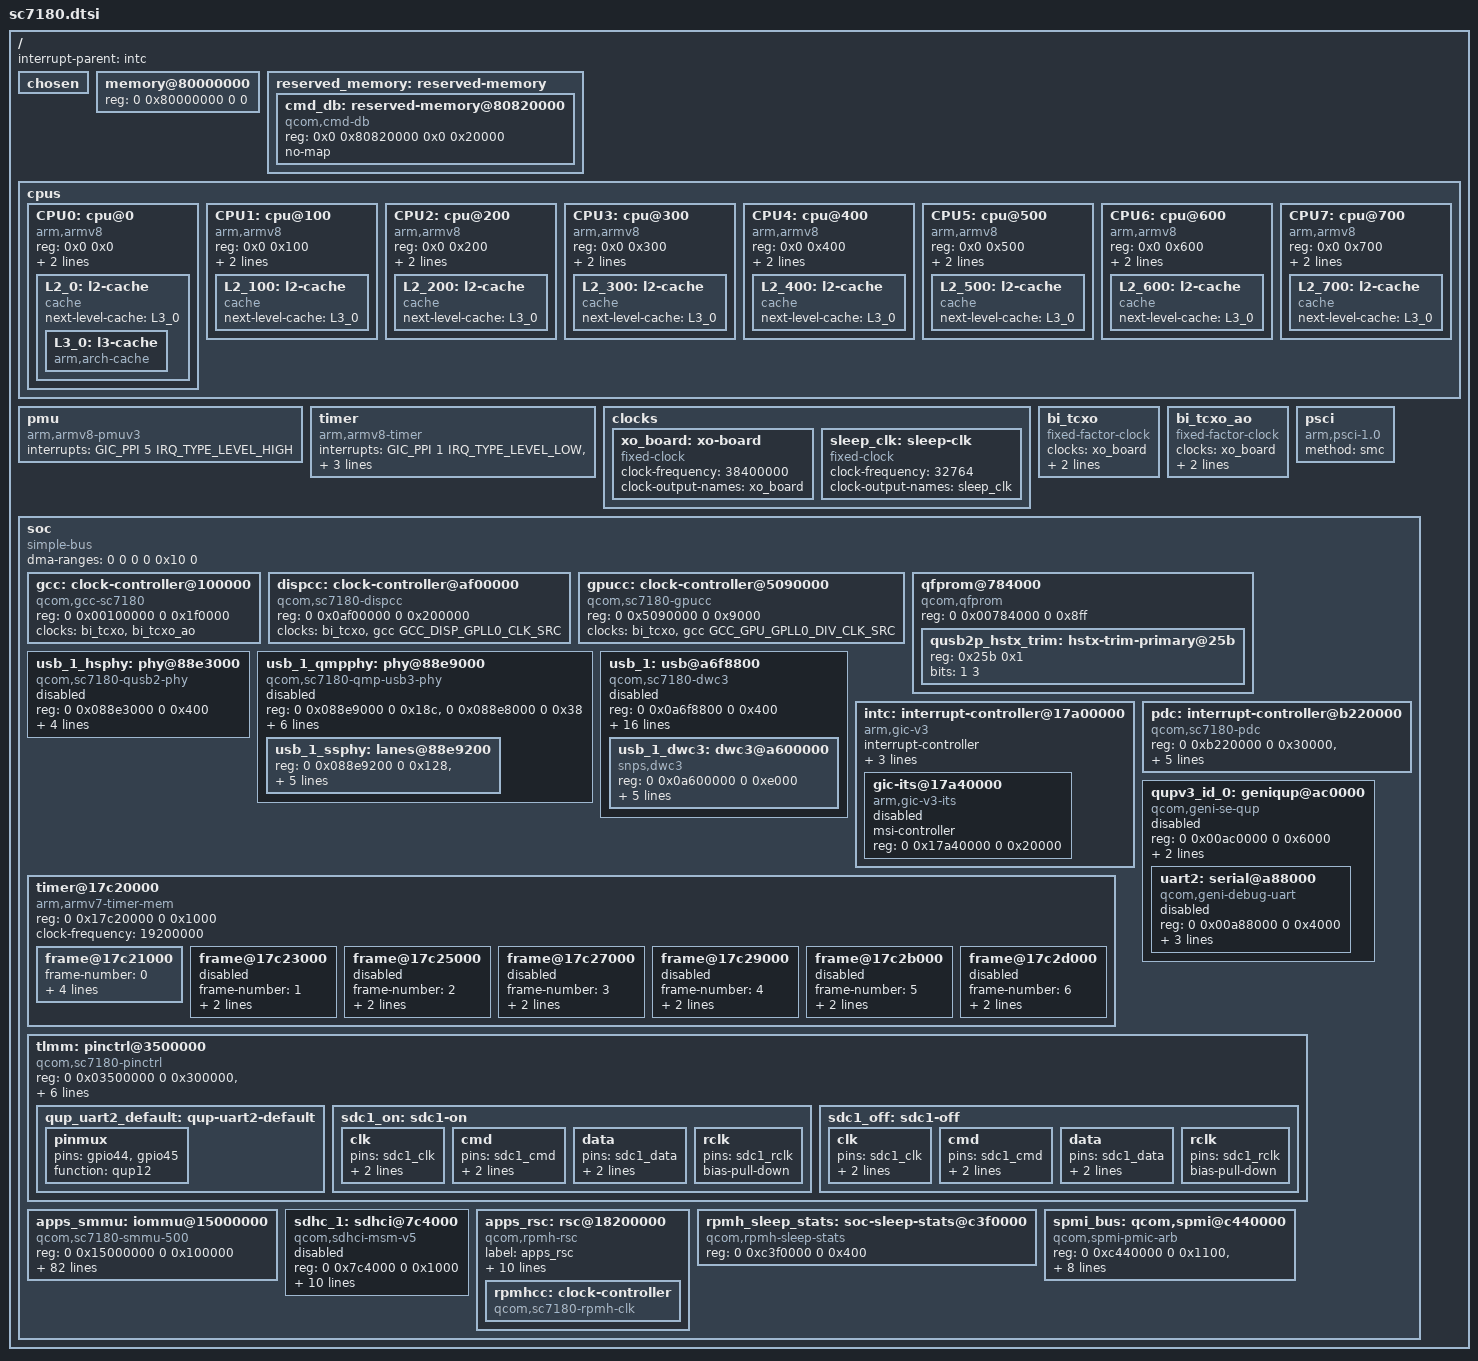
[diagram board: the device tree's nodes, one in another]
// SPDX-License-Identifier: GPL-2.0
/*
 * SC7180 SoC device tree source
 *
 * Copyright (c) 2019, The Linux Foundation. All rights reserved.
 */

#include <dt-bindings/interrupt-controller/arm-gic.h>
#include <dt-bindings/clock/qcom,dispcc-sc7180.h>
#include <dt-bindings/clock/qcom,gcc-sc7180.h>
#include <dt-bindings/clock/qcom,gpucc-sc7180.h>
#include <dt-bindings/soc/qcom,rpmh-rsc.h>
#include <dt-bindings/phy/phy-qcom-qusb2.h>

/ {
	interrupt-parent = <&intc>;

	#address-cells = <2>;
	#size-cells = <2>;

	chosen { };

	memory@80000000 {
		device_type = "memory";
		/* We expect the bootloader to fill in the size */
		reg = <0 0x80000000 0 0>;
	};

	reserved_memory: reserved-memory {
		#address-cells = <2>;
		#size-cells = <2>;
		ranges;

		cmd_db: reserved-memory@80820000 {
			reg = <0x0 0x80820000 0x0 0x20000>;
			compatible = "qcom,cmd-db";
			no-map;
		};
	};

	cpus {
		#address-cells = <2>;
		#size-cells = <0>;

		CPU0: cpu@0 {
			device_type = "cpu";
			compatible = "arm,armv8";
			reg = <0x0 0x0>;
			enable-method = "psci";
			next-level-cache = <&L2_0>;
			L2_0: l2-cache {
				compatible = "cache";
				next-level-cache = <&L3_0>;
				L3_0: l3-cache {
					compatible = "arm,arch-cache";
				};
			};
		};

		CPU1: cpu@100 {
			device_type = "cpu";
			compatible = "arm,armv8";
			reg = <0x0 0x100>;
			enable-method = "psci";
			next-level-cache = <&L2_100>;
			L2_100: l2-cache {
				compatible = "cache";
				next-level-cache = <&L3_0>;
			};
		};

		CPU2: cpu@200 {
			device_type = "cpu";
			compatible = "arm,armv8";
			reg = <0x0 0x200>;
			enable-method = "psci";
			next-level-cache = <&L2_200>;
			L2_200: l2-cache {
				compatible = "cache";
				next-level-cache = <&L3_0>;
			};
		};

		CPU3: cpu@300 {
			device_type = "cpu";
			compatible = "arm,armv8";
			reg = <0x0 0x300>;
			enable-method = "psci";
			next-level-cache = <&L2_300>;
			L2_300: l2-cache {
				compatible = "cache";
				next-level-cache = <&L3_0>;
			};
		};

		CPU4: cpu@400 {
			device_type = "cpu";
			compatible = "arm,armv8";
			reg = <0x0 0x400>;
			enable-method = "psci";
			next-level-cache = <&L2_400>;
			L2_400: l2-cache {
				compatible = "cache";
				next-level-cache = <&L3_0>;
			};
		};

		CPU5: cpu@500 {
			device_type = "cpu";
			compatible = "arm,armv8";
			reg = <0x0 0x500>;
			enable-method = "psci";
			next-level-cache = <&L2_500>;
			L2_500: l2-cache {
				compatible = "cache";
				next-level-cache = <&L3_0>;
			};
		};

		CPU6: cpu@600 {
			device_type = "cpu";
			compatible = "arm,armv8";
			reg = <0x0 0x600>;
			enable-method = "psci";
			next-level-cache = <&L2_600>;
			L2_600: l2-cache {
				compatible = "cache";
				next-level-cache = <&L3_0>;
			};
		};

		CPU7: cpu@700 {
			device_type = "cpu";
			compatible = "arm,armv8";
			reg = <0x0 0x700>;
			enable-method = "psci";
			next-level-cache = <&L2_700>;
			L2_700: l2-cache {
				compatible = "cache";
				next-level-cache = <&L3_0>;
			};
		};
	};

	pmu {
		compatible = "arm,armv8-pmuv3";
		interrupts = <GIC_PPI 5 IRQ_TYPE_LEVEL_HIGH>;
	};

	timer {
		compatible = "arm,armv8-timer";
		interrupts = <GIC_PPI 1 IRQ_TYPE_LEVEL_LOW>,
			     <GIC_PPI 2 IRQ_TYPE_LEVEL_LOW>,
			     <GIC_PPI 3 IRQ_TYPE_LEVEL_LOW>,
			     <GIC_PPI 0 IRQ_TYPE_LEVEL_LOW>;
	};

	clocks {
		xo_board: xo-board {
			compatible = "fixed-clock";
			clock-frequency = <38400000>;
			clock-output-names = "xo_board";
			#clock-cells = <0>;
		};

		sleep_clk: sleep-clk {
			compatible = "fixed-clock";
			clock-frequency = <32764>;
			clock-output-names = "sleep_clk";
			#clock-cells = <0>;
		};
	};

	bi_tcxo: bi_tcxo {
		compatible = "fixed-factor-clock";
		clocks = <&xo_board>;
		clock-mult = <1>;
		clock-div = <2>;
		#clock-cells = <0>;
	};

	bi_tcxo_ao: bi_tcxo_ao {
		compatible = "fixed-factor-clock";
		clocks = <&xo_board>;
		clock-mult = <1>;
		clock-div = <2>;
		#clock-cells = <0>;
	};

	psci {
		compatible = "arm,psci-1.0";
		method = "smc";
	};

	soc: soc {
		#address-cells = <2>;
		#size-cells = <2>;
		ranges = <0 0 0 0 0x10 0>;
		dma-ranges = <0 0 0 0  0x10 0>;
		compatible = "simple-bus";

		gcc: clock-controller@100000 {
			compatible = "qcom,gcc-sc7180";
			reg = <0 0x00100000 0 0x1f0000>;
			clocks = <&bi_tcxo>, <&bi_tcxo_ao>;
			clock-names = "bi_tcxo", "bi_tcxo_ao";
			#clock-cells = <1>;
			#reset-cells = <1>;
			#power-domain-cells = <1>;
		};

		dispcc: clock-controller@af00000 {
			compatible = "qcom,sc7180-dispcc";
			reg = <0 0x0af00000 0 0x200000>;
			clocks = <&bi_tcxo>, <&gcc GCC_DISP_GPLL0_CLK_SRC>;
			clock-names = "bi_tcxo", "gcc_disp_gpll0_clk_src";
			#clock-cells = <1>;
			#reset-cells = <1>;
			#power-domain-cells = <1>;
		};

		gpucc: clock-controller@5090000 {
			compatible = "qcom,sc7180-gpucc";
			reg = <0 0x5090000 0 0x9000>;
			clocks = <&bi_tcxo>, <&gcc GCC_GPU_GPLL0_DIV_CLK_SRC>;
			clock-names = "bi_tcxo", "gcc_gpu_gpll0_div_clk_src";
			#clock-cells = <1>;
			#reset-cells = <1>;
			#power-domain-cells = <1>;
		};

		qfprom@784000 {
			compatible = "qcom,qfprom";
			reg = <0 0x00784000 0 0x8ff>;
			#address-cells = <1>;
			#size-cells = <1>;

			qusb2p_hstx_trim: hstx-trim-primary@25b {
				reg = <0x25b 0x1>;
				bits = <1 3>;
			};
		};

		usb_1_hsphy: phy@88e3000 {
			compatible = "qcom,sc7180-qusb2-phy";
			reg = <0 0x088e3000 0 0x400>;
			status = "disabled";
			#phy-cells = <0>;
			clocks = <&gcc GCC_USB_PHY_CFG_AHB2PHY_CLK>,
			<&bi_tcxo>;
			clock-names = "cfg_ahb","ref";
			resets = <&gcc GCC_QUSB2PHY_PRIM_BCR>;

			nvmem-cells = <&qusb2p_hstx_trim>;
		};

		usb_1_qmpphy: phy@88e9000 {
			compatible = "qcom,sc7180-qmp-usb3-phy";
			reg = <0 0x088e9000 0 0x18c>,
			      <0 0x088e8000 0 0x38>;
			reg-names = "reg-base", "dp_com";
			status = "disabled";
			#clock-cells = <1>;
			#address-cells = <2>;
			#size-cells = <2>;
			ranges;

			clocks = <&gcc GCC_USB3_PRIM_PHY_AUX_CLK>,
				 <&gcc GCC_USB_PHY_CFG_AHB2PHY_CLK>,
				 <&gcc GCC_USB3_PRIM_CLKREF_CLK>,
				 <&gcc GCC_USB3_PRIM_PHY_COM_AUX_CLK>;
			clock-names = "aux", "cfg_ahb", "ref", "com_aux";

			resets = <&gcc GCC_USB3_DP_PHY_PRIM_BCR>,
				 <&gcc GCC_USB3_PHY_PRIM_BCR>;
			reset-names = "phy", "common";

			usb_1_ssphy: lanes@88e9200 {
				reg = <0 0x088e9200 0 0x128>,
				      <0 0x088e9400 0 0x200>,
				      <0 0x088e9c00 0 0x218>,
				      <0 0x088e9600 0 0x128>,
				      <0 0x088e9800 0 0x200>,
				      <0 0x088e9a00 0 0x18>;
				#phy-cells = <0>;
				clocks = <&gcc GCC_USB3_PRIM_PHY_PIPE_CLK>;
				clock-names = "pipe0";
				clock-output-names = "usb3_phy_pipe_clk_src";
			};
		};

		usb_1: usb@a6f8800 {
			compatible = "qcom,sc7180-dwc3", "qcom,dwc3";
			reg = <0 0x0a6f8800 0 0x400>;
			status = "disabled";
			#address-cells = <2>;
			#size-cells = <2>;
			ranges;
			dma-ranges;

			clocks = <&gcc GCC_CFG_NOC_USB3_PRIM_AXI_CLK>,
				 <&gcc GCC_USB30_PRIM_MASTER_CLK>,
				 <&gcc GCC_AGGRE_USB3_PRIM_AXI_CLK>,
				 <&gcc GCC_USB30_PRIM_MOCK_UTMI_CLK>,
				 <&gcc GCC_USB30_PRIM_SLEEP_CLK>;
			clock-names = "cfg_noc", "core", "iface", "mock_utmi",
				      "sleep";

			assigned-clocks = <&gcc GCC_USB30_PRIM_MOCK_UTMI_CLK>,
					  <&gcc GCC_USB30_PRIM_MASTER_CLK>;
			assigned-clock-rates = <19200000>, <150000000>;

			interrupts = <GIC_SPI 131 IRQ_TYPE_LEVEL_HIGH>,
				     <GIC_SPI 486 IRQ_TYPE_LEVEL_HIGH>,
				     <GIC_SPI 488 IRQ_TYPE_LEVEL_HIGH>,
				     <GIC_SPI 489 IRQ_TYPE_LEVEL_HIGH>;
			interrupt-names = "hs_phy_irq", "ss_phy_irq",
					  "dm_hs_phy_irq", "dp_hs_phy_irq";

			power-domains = <&gcc USB30_PRIM_GDSC>;

			resets = <&gcc GCC_USB30_PRIM_BCR>;

			usb_1_dwc3: dwc3@a600000 {
				compatible = "snps,dwc3";
				reg = <0 0x0a600000 0 0xe000>;
				interrupts = <GIC_SPI 133 IRQ_TYPE_LEVEL_HIGH>;
				iommus = <&apps_smmu 0x540 0>;
				snps,dis_u2_susphy_quirk;
				snps,dis_enblslpm_quirk;
				phys = <&usb_1_hsphy>, <&usb_1_ssphy>;
				phy-names = "usb2-phy", "usb3-phy";
			};
		};

		intc: interrupt-controller@17a00000 {
			compatible = "arm,gic-v3";
			#address-cells = <2>;
			#size-cells = <2>;
			ranges;
			#interrupt-cells = <3>;
			interrupt-controller;
			reg = <0 0x17a00000 0 0x10000>,     /* GICD */
			      <0 0x17a60000 0 0x100000>;    /* GICR * 8 */
			interrupts = <GIC_PPI 9 IRQ_TYPE_LEVEL_HIGH>;

			gic-its@17a40000 {
				compatible = "arm,gic-v3-its";
				msi-controller;
				#msi-cells = <1>;
				reg = <0 0x17a40000 0 0x20000>;
				status = "disabled";
			};
		};

		pdc: interrupt-controller@b220000 {
			compatible = "qcom,sc7180-pdc";
			reg = <0 0xb220000 0 0x30000>,
			      <0 0x17c000f0 0 0x60>;
			qcom,pdc-ranges = <0 480 15>, <17 497 98>,
					  <119 634 4>, <124 639 1>;
			#interrupt-cells = <2>;
			interrupt-parent = <&intc>;
			interrupt-controller;
		};

		timer@17c20000{
			#address-cells = <2>;
			#size-cells = <2>;
			ranges;
			compatible = "arm,armv7-timer-mem";
			reg = <0 0x17c20000 0 0x1000>;
			clock-frequency = <19200000>;

			frame@17c21000 {
				frame-number = <0>;
				interrupts = <GIC_SPI 8 IRQ_TYPE_LEVEL_HIGH>,
					     <GIC_SPI 6 IRQ_TYPE_LEVEL_HIGH>;
				reg = <0 0x17c21000 0 0x1000>,
				      <0 0x17c22000 0 0x1000>;
			};

			frame@17c23000 {
				frame-number = <1>;
				interrupts = <GIC_SPI 9 IRQ_TYPE_LEVEL_HIGH>;
				reg = <0 0x17c23000 0 0x1000>;
				status = "disabled";
			};

			frame@17c25000 {
				frame-number = <2>;
				interrupts = <GIC_SPI 10 IRQ_TYPE_LEVEL_HIGH>;
				reg = <0 0x17c25000 0 0x1000>;
				status = "disabled";
			};

			frame@17c27000 {
				frame-number = <3>;
				interrupts = <GIC_SPI 11 IRQ_TYPE_LEVEL_HIGH>;
				reg = <0 0x17c27000 0 0x1000>;
				status = "disabled";
			};

			frame@17c29000 {
				frame-number = <4>;
				interrupts = <GIC_SPI 12 IRQ_TYPE_LEVEL_HIGH>;
				reg = <0 0x17c29000 0 0x1000>;
				status = "disabled";
			};

			frame@17c2b000 {
				frame-number = <5>;
				interrupts = <GIC_SPI 13 IRQ_TYPE_LEVEL_HIGH>;
				reg = <0 0x17c2b000 0 0x1000>;
				status = "disabled";
			};

			frame@17c2d000 {
				frame-number = <6>;
				interrupts = <GIC_SPI 14 IRQ_TYPE_LEVEL_HIGH>;
				reg = <0 0x17c2d000 0 0x1000>;
				status = "disabled";
			};
		};

		qupv3_id_0: geniqup@ac0000 {
			compatible = "qcom,geni-se-qup";
			reg = <0 0x00ac0000 0 0x6000>;
			clock-names = "m-ahb", "s-ahb";
			clocks = <&gcc GCC_QUPV3_WRAP_1_M_AHB_CLK>,
				 <&gcc GCC_QUPV3_WRAP_1_S_AHB_CLK>;
			#address-cells = <2>;
			#size-cells = <2>;
			ranges;
			status = "disabled";

			uart2: serial@a88000 {
				compatible = "qcom,geni-debug-uart";
				reg = <0 0x00a88000 0 0x4000>;
				clock-names = "se";
				clocks = <&gcc GCC_QUPV3_WRAP1_S2_CLK>;
				pinctrl-names = "default";
				pinctrl-0 = <&qup_uart2_default>;
				interrupts = <GIC_SPI 355 IRQ_TYPE_LEVEL_HIGH>;
				status = "disabled";
			};
		};

		tlmm: pinctrl@3500000 {
			compatible = "qcom,sc7180-pinctrl";
			reg = <0 0x03500000 0 0x300000>,
			      <0 0x03900000 0 0x300000>,
			      <0 0x03d00000 0 0x300000>;
			reg-names = "west", "north", "south";
			interrupts = <GIC_SPI 208 IRQ_TYPE_LEVEL_HIGH>;
			gpio-controller;
			#gpio-cells = <2>;
			interrupt-controller;
			#interrupt-cells = <2>;
			gpio-ranges = <&tlmm 0 0 120>;

			qup_uart2_default: qup-uart2-default {
				pinmux {
					pins = "gpio44", "gpio45";
					function = "qup12";
				};
			};

			sdc1_on: sdc1-on {
				clk {
					pins = "sdc1_clk";
					bias-disable;
					drive-strength = <16>;
				};

				cmd {
					pins = "sdc1_cmd";
					bias-pull-up;
					drive-strength = <10>;
				};

				data {
					pins = "sdc1_data";
					bias-pull-up;
					dreive-strength = <10>;
				};

				rclk {
					pins = "sdc1_rclk";
					bias-pull-down;
				};
			};

			sdc1_off: sdc1-off {
				clk {
					pins = "sdc1_clk";
					bias-disable;
					drive-strength = <2>;
				};

				cmd {
					pins = "sdc1_cmd";
					bias-pull-up;
					drive-strength = <2>;
				};

				data {
					pins = "sdc1_data";
					bias-pull-up;
					dreive-strength = <2>;
				};

				rclk {
					pins = "sdc1_rclk";
					bias-pull-down;
				};
			};
		};

		apps_smmu: iommu@15000000 {
			compatible = "qcom,sc7180-smmu-500", "arm,mmu-500";
			reg = <0 0x15000000 0 0x100000>;
			#iommu-cells = <2>;
			#global-interrupts = <1>;
			interrupts = <GIC_SPI 65 IRQ_TYPE_LEVEL_HIGH>,
				     <GIC_SPI 94 IRQ_TYPE_LEVEL_HIGH>,
				     <GIC_SPI 95 IRQ_TYPE_LEVEL_HIGH>,
				     <GIC_SPI 96 IRQ_TYPE_LEVEL_HIGH>,
				     <GIC_SPI 97 IRQ_TYPE_LEVEL_HIGH>,
				     <GIC_SPI 98 IRQ_TYPE_LEVEL_HIGH>,
				     <GIC_SPI 99 IRQ_TYPE_LEVEL_HIGH>,
				     <GIC_SPI 100 IRQ_TYPE_LEVEL_HIGH>,
				     <GIC_SPI 101 IRQ_TYPE_LEVEL_HIGH>,
				     <GIC_SPI 102 IRQ_TYPE_LEVEL_HIGH>,
				     <GIC_SPI 103 IRQ_TYPE_LEVEL_HIGH>,
				     <GIC_SPI 104 IRQ_TYPE_LEVEL_HIGH>,
				     <GIC_SPI 105 IRQ_TYPE_LEVEL_HIGH>,
				     <GIC_SPI 106 IRQ_TYPE_LEVEL_HIGH>,
				     <GIC_SPI 107 IRQ_TYPE_LEVEL_HIGH>,
				     <GIC_SPI 108 IRQ_TYPE_LEVEL_HIGH>,
				     <GIC_SPI 109 IRQ_TYPE_LEVEL_HIGH>,
				     <GIC_SPI 110 IRQ_TYPE_LEVEL_HIGH>,
				     <GIC_SPI 111 IRQ_TYPE_LEVEL_HIGH>,
				     <GIC_SPI 112 IRQ_TYPE_LEVEL_HIGH>,
				     <GIC_SPI 113 IRQ_TYPE_LEVEL_HIGH>,
				     <GIC_SPI 114 IRQ_TYPE_LEVEL_HIGH>,
				     <GIC_SPI 115 IRQ_TYPE_LEVEL_HIGH>,
				     <GIC_SPI 116 IRQ_TYPE_LEVEL_HIGH>,
				     <GIC_SPI 117 IRQ_TYPE_LEVEL_HIGH>,
				     <GIC_SPI 118 IRQ_TYPE_LEVEL_HIGH>,
				     <GIC_SPI 181 IRQ_TYPE_LEVEL_HIGH>,
				     <GIC_SPI 182 IRQ_TYPE_LEVEL_HIGH>,
				     <GIC_SPI 183 IRQ_TYPE_LEVEL_HIGH>,
				     <GIC_SPI 184 IRQ_TYPE_LEVEL_HIGH>,
				     <GIC_SPI 185 IRQ_TYPE_LEVEL_HIGH>,
				     <GIC_SPI 186 IRQ_TYPE_LEVEL_HIGH>,
				     <GIC_SPI 187 IRQ_TYPE_LEVEL_HIGH>,
				     <GIC_SPI 188 IRQ_TYPE_LEVEL_HIGH>,
				     <GIC_SPI 189 IRQ_TYPE_LEVEL_HIGH>,
				     <GIC_SPI 190 IRQ_TYPE_LEVEL_HIGH>,
				     <GIC_SPI 191 IRQ_TYPE_LEVEL_HIGH>,
				     <GIC_SPI 192 IRQ_TYPE_LEVEL_HIGH>,
				     <GIC_SPI 315 IRQ_TYPE_LEVEL_HIGH>,
				     <GIC_SPI 316 IRQ_TYPE_LEVEL_HIGH>,
				     <GIC_SPI 317 IRQ_TYPE_LEVEL_HIGH>,
				     <GIC_SPI 318 IRQ_TYPE_LEVEL_HIGH>,
				     <GIC_SPI 319 IRQ_TYPE_LEVEL_HIGH>,
				     <GIC_SPI 320 IRQ_TYPE_LEVEL_HIGH>,
				     <GIC_SPI 321 IRQ_TYPE_LEVEL_HIGH>,
				     <GIC_SPI 322 IRQ_TYPE_LEVEL_HIGH>,
				     <GIC_SPI 323 IRQ_TYPE_LEVEL_HIGH>,
				     <GIC_SPI 324 IRQ_TYPE_LEVEL_HIGH>,
				     <GIC_SPI 325 IRQ_TYPE_LEVEL_HIGH>,
				     <GIC_SPI 326 IRQ_TYPE_LEVEL_HIGH>,
				     <GIC_SPI 327 IRQ_TYPE_LEVEL_HIGH>,
				     <GIC_SPI 328 IRQ_TYPE_LEVEL_HIGH>,
				     <GIC_SPI 329 IRQ_TYPE_LEVEL_HIGH>,
				     <GIC_SPI 330 IRQ_TYPE_LEVEL_HIGH>,
				     <GIC_SPI 331 IRQ_TYPE_LEVEL_HIGH>,
				     <GIC_SPI 332 IRQ_TYPE_LEVEL_HIGH>,
				     <GIC_SPI 333 IRQ_TYPE_LEVEL_HIGH>,
				     <GIC_SPI 334 IRQ_TYPE_LEVEL_HIGH>,
				     <GIC_SPI 335 IRQ_TYPE_LEVEL_HIGH>,
				     <GIC_SPI 336 IRQ_TYPE_LEVEL_HIGH>,
				     <GIC_SPI 337 IRQ_TYPE_LEVEL_HIGH>,
				     <GIC_SPI 338 IRQ_TYPE_LEVEL_HIGH>,
				     <GIC_SPI 339 IRQ_TYPE_LEVEL_HIGH>,
				     <GIC_SPI 340 IRQ_TYPE_LEVEL_HIGH>,
				     <GIC_SPI 341 IRQ_TYPE_LEVEL_HIGH>,
				     <GIC_SPI 342 IRQ_TYPE_LEVEL_HIGH>,
				     <GIC_SPI 343 IRQ_TYPE_LEVEL_HIGH>,
				     <GIC_SPI 344 IRQ_TYPE_LEVEL_HIGH>,
				     <GIC_SPI 345 IRQ_TYPE_LEVEL_HIGH>,
				     <GIC_SPI 401 IRQ_TYPE_LEVEL_HIGH>,
				     <GIC_SPI 402 IRQ_TYPE_LEVEL_HIGH>,
				     <GIC_SPI 403 IRQ_TYPE_LEVEL_HIGH>,
				     <GIC_SPI 404 IRQ_TYPE_LEVEL_HIGH>,
				     <GIC_SPI 405 IRQ_TYPE_LEVEL_HIGH>,
				     <GIC_SPI 406 IRQ_TYPE_LEVEL_HIGH>,
				     <GIC_SPI 407 IRQ_TYPE_LEVEL_HIGH>,
				     <GIC_SPI 408 IRQ_TYPE_LEVEL_HIGH>,
				     <GIC_SPI 409 IRQ_TYPE_LEVEL_HIGH>,
				     <GIC_SPI 410 IRQ_TYPE_LEVEL_HIGH>,
				     <GIC_SPI 411 IRQ_TYPE_LEVEL_HIGH>,
				     <GIC_SPI 412 IRQ_TYPE_LEVEL_HIGH>;
		};

		sdhc_1: sdhci@7c4000 {
			compatible = "qcom,sdhci-msm-v5";
			reg = <0 0x7c4000 0 0x1000>;
			reg-names = "hc_mem";

			interrupts = <GIC_SPI 641 IRQ_TYPE_LEVEL_HIGH>,
						<GIC_SPI 644 IRQ_TYPE_LEVEL_HIGH>;
			interrupt-names = "hc_irq", "pwr_irq";

			clocks = <&gcc GCC_SDCC1_APPS_CLK>,
					<&gcc GCC_SDCC1_AHB_CLK>;
			clock-names = "core", "iface";

			bus-width = <8>;
			non-removable;

			mmc-ddr-1_8v;
			mmc-hs200-1_8v;
			mmc-hs400-1_8v;
			mmc-hs400-enhanced-strobe;

			status = "disabled";
		};

		apps_rsc: rsc@18200000 {
			label = "apps_rsc";
			compatible = "qcom,rpmh-rsc";
			reg = <0 0x18200000 0 0x10000>,
			      <0 0x18210000 0 0x10000>,
			      <0 0x18220000 0 0x10000>;
			reg-names = "drv-0", "drv-1", "drv-2";
			interrupts = <GIC_SPI 3 IRQ_TYPE_LEVEL_HIGH>,
				     <GIC_SPI 4 IRQ_TYPE_LEVEL_HIGH>,
				     <GIC_SPI 5 IRQ_TYPE_LEVEL_HIGH>;
			qcom,tcs-offset = <0xd00>;
			qcom,drv-id = <2>;
			qcom,tcs-config = <ACTIVE_TCS  2>,
					  <SLEEP_TCS   3>,
					  <WAKE_TCS    3>,
					  <CONTROL_TCS 1>;

			rpmhcc: clock-controller {
			    compatible = "qcom,sc7180-rpmh-clk";
			    #clock-cells = <1>;
			};
		};

		rpmh_sleep_stats: soc-sleep-stats@c3f0000 {
			compatible = "qcom,rpmh-sleep-stats";
			reg = <0 0xc3f0000 0 0x400>;
		};

		spmi_bus: qcom,spmi@c440000 {
			compatible = "qcom,spmi-pmic-arb";
			reg = <0 0xc440000 0 0x1100>,
				<0 0xc600000 0 0x2000000>,
				<0 0xe600000 0 0x100000>,
				<0 0xe700000 0 0xa0000>,
				<0 0xc40a000 0 0x26000>;
			reg-names = "core", "chnls", "obsrvr", "intr", "cnfg";
			interrupt-names = "periph_irq";
			interrupts-extended = <&pdc 1 IRQ_TYPE_LEVEL_HIGH>;
			qcom,ee = <0>;
			qcom,channel = <0>;
			#address-cells = <1>;
			#size-cells = <1>;
			interrupt-controller;
			#interrupt-cells = <4>;
			cell-index = <0>;
		};
	};
};

#include "pm6150.dtsi"
#include "pm6150l.dtsi"
#include "sc7180-regulator.dtsi"
